VERSION ""

NS_ :

BS_:

BU_: BMS Third_Party_Device

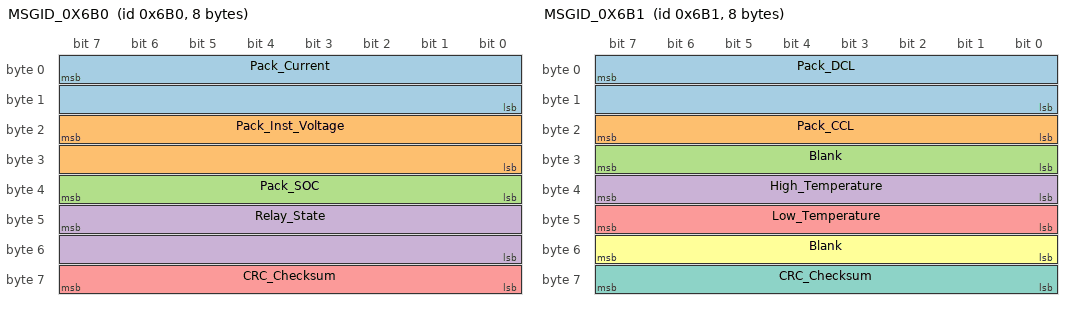
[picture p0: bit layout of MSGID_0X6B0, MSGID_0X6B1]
BO_ 1712 MSGID_0X6B0: 8 BMS
 SG_ Pack_Current : 7|16@0+ (0.1,0) [0|0] "Amps"  Third_Party_Device
 SG_ Pack_Inst_Voltage : 23|16@0+ (0.1,0) [0|0] "Volts"  Third_Party_Device
 SG_ Pack_SOC : 39|8@0+ (0.5,0) [0|0] "Percent"  Third_Party_Device
 SG_ Relay_State : 47|16@0+ (1.0,0) [0|0] ""  Third_Party_Device
 SG_ CRC_Checksum : 63|8@0+ (1.0,1720) [0|0] ""  Third_Party_Device

BO_ 1713 MSGID_0X6B1: 8 BMS
 SG_ Pack_DCL : 7|16@0+ (1.0,0) [0|0] "Amps"  Third_Party_Device
 SG_ Pack_CCL : 23|8@0+ (1.0,0) [0|0] "Amps"  Third_Party_Device
 SG_ Blank : 31|8@0+ (1.0,0) [0|0] ""  Third_Party_Device
 SG_ High_Temperature : 39|8@0+ (1.0,0) [0|0] "Celsius"  Third_Party_Device
 SG_ Low_Temperature : 47|8@0+ (1.0,0) [0|0] "Celsius"  Third_Party_Device
 SG_ Blank : 55|8@0+ (1.0,0) [0|0] ""  Third_Party_Device
 SG_ CRC_Checksum : 63|8@0+ (1.0,1721) [0|0] ""  Third_Party_Device

CM_ BO_ 1712 "This ID Transmits at 8 ms.";
CM_ BO_ 1713 "This ID Transmits at 104 ms.";
CM_ BO_ 2550589428 "This ID Transmits at 808 ms.";
CM_ BO_ 2550588916 "This ID Transmits at 808 ms.";
CM_ BO_ 2550589940 "This ID Transmits at 808 ms.";
